# XHSC_HC32A052 register map
Vendor: XHSC Co.Ltd; Series: ARMCM4; File version: 1.2
CPU: CM0 r0p0, little endian, no MPU, no FPU, 3 interrupt priority bits
Registers are 32-bit, read-write, reset 0x0 unless marked. A register's access mark holds for its fields unless they carry their own. Offsets are from the block's base; [hi:lo] are bit positions; {n}, {i} and the like mark numbered series; 'fields as' and 'values as' point back to an identical list.

## RTC
Base 0x40001400
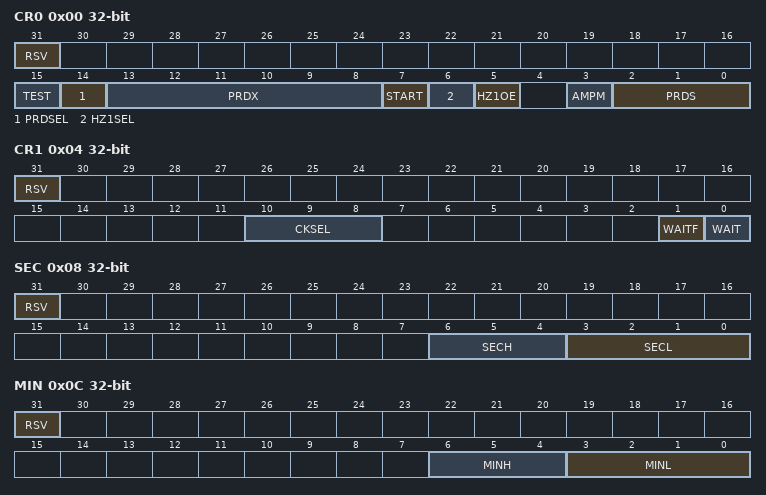
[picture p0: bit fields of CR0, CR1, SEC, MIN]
0x00 CR0 (reset mask 0xFFEF)
  [31] RSV, [15] TEST, [14] PRDSEL, [13:8] PRDX, [7] START, [6] HZ1SEL, [5] HZ1OE, [3] AMPM, [2:0] PRDS
0x04 CR1 (reset mask 0x303)
  [31] RSV, [10:8] CKSEL, [1] WAITF, [0] WAIT
0x08 SEC (reset mask 0x7F)
  [31] RSV, [6:4] SECH, [3:0] SECL
0x0C MIN (reset mask 0x7F)
  [31] RSV, [6:4] MINH, [3:0] MINL
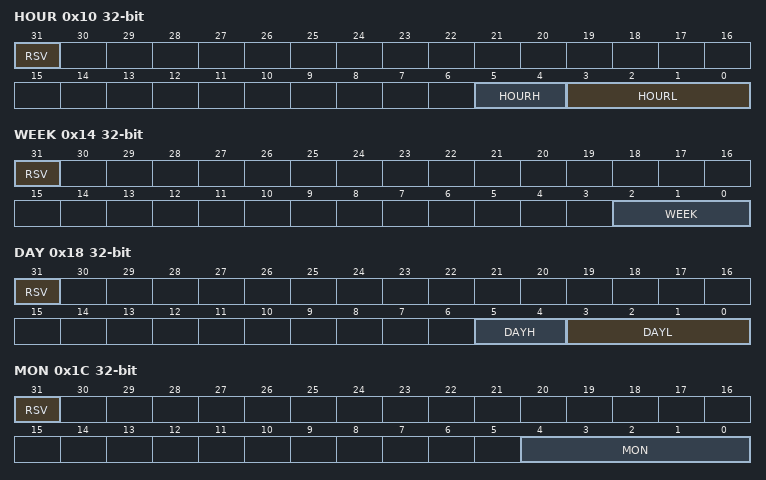
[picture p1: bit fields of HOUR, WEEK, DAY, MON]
0x10 HOUR (reset mask 0x3F)
  [31] RSV, [5:4] HOURH, [3:0] HOURL
0x14 WEEK (reset mask 0x7)
  [31] RSV, [2:0] WEEK
0x18 DAY (reset mask 0x3F)
  [31] RSV, [5:4] DAYH, [3:0] DAYL
0x1C MON (reset mask 0x1F)
  [31] RSV, [4:0] MON
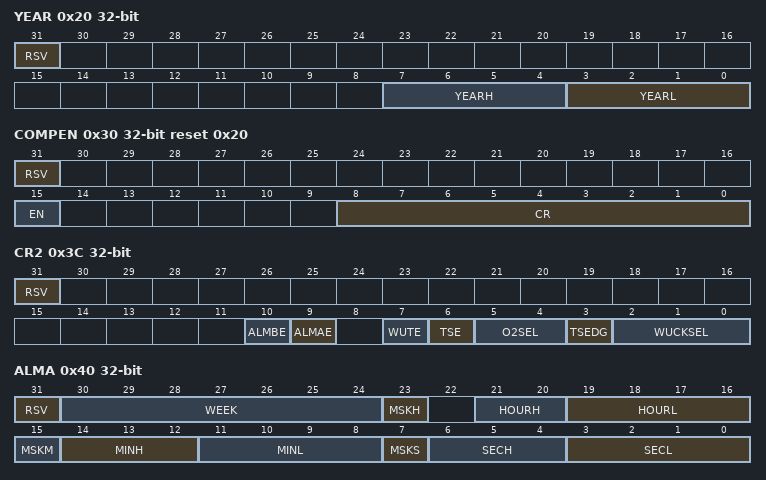
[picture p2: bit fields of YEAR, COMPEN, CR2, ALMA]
0x20 YEAR (reset mask 0xFF)
  [31] RSV, [7:4] YEARH, [3:0] YEARL
0x30 COMPEN reset 0x20 (reset mask 0x18FF)
  [31] RSV, [15] EN, [8:0] CR
0x3C CR2 (reset mask 0x6FF)
  [31] RSV, [10] ALMBE, [9] ALMAE, [7] WUTE, [6] TSE, [5:4] O2SEL, [3] TSEDG, [2:0] WUCKSEL
0x40 ALMA (reset mask 0x7FBFFFFF)
  [31] RSV, [30:24] WEEK, [23] MSKH, [21:20] HOURH, [19:16] HOURL, [15] MSKM, [14:12] MINH, [11:8] MINL, [7] MSKS, [6:4] SECH, [3:0] SECL
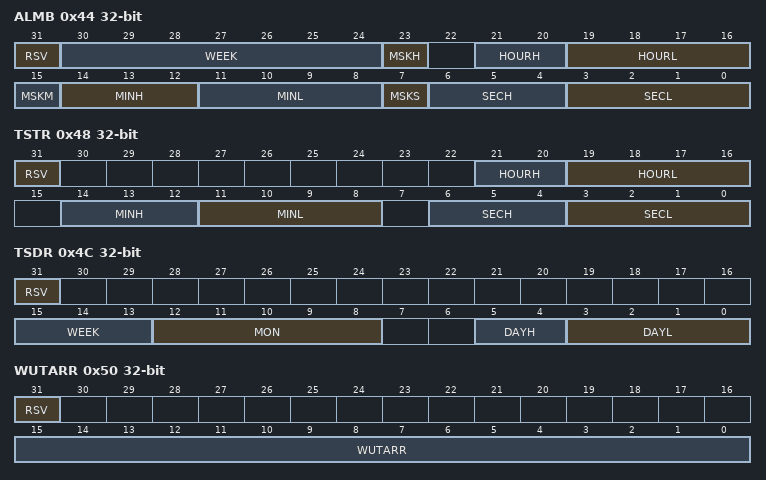
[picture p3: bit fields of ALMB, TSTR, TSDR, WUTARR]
0x44 ALMB (reset mask 0x7FBFFFFF)
  fields as ALMA
0x48 TSTR ro (reset mask 0x3F7F7F)
  [31] RSV, [21:20] HOURH, [19:16] HOURL, [14:12] MINH, [11:8] MINL, [6:4] SECH, [3:0] SECL
0x4C TSDR ro (reset mask 0xFF3F)
  [31] RSV, [15:13] WEEK, [12:8] MON, [5:4] DAYH, [3:0] DAYL
0x50 WUTARR (reset mask 0xFFFF)
  [31] RSV, [15:0] WUTARR
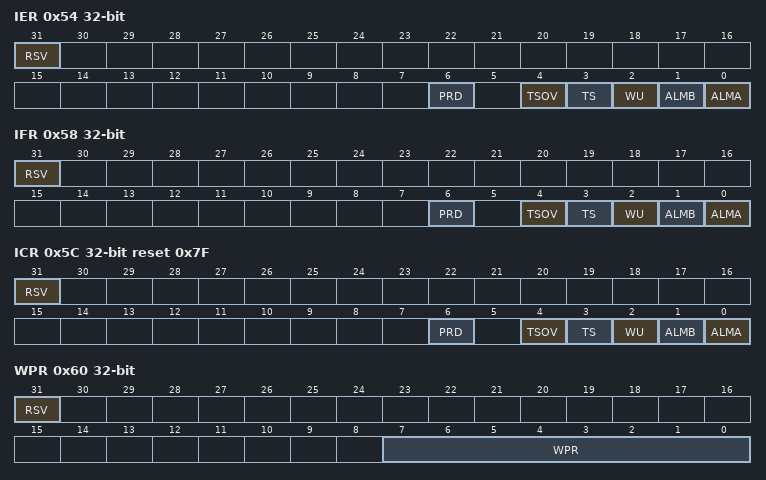
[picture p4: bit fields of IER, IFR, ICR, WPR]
0x54 IER (reset mask 0x5F)
  [31] RSV, [6] PRD, [4] TSOV, [3] TS, [2] WU, [1] ALMB, [0] ALMA
0x58 IFR ro (reset mask 0x5F)
  [31] RSV, [6] PRD, [4] TSOV, [3] TS, [2] WU, [1] ALMB, [0] ALMA
0x5C ICR reset 0x7F (reset mask 0x5F)
  [31] RSV, [6] PRD, [4] TSOV, [3] TS, [2] WU, [1] ALMB, [0] ALMA
0x60 WPR (reset mask 0xFF)
  [31] RSV, [7:0] WPR

## SPI0 — desc SPI
Base 0x40000800
Same registers: SPI1 0x40004800
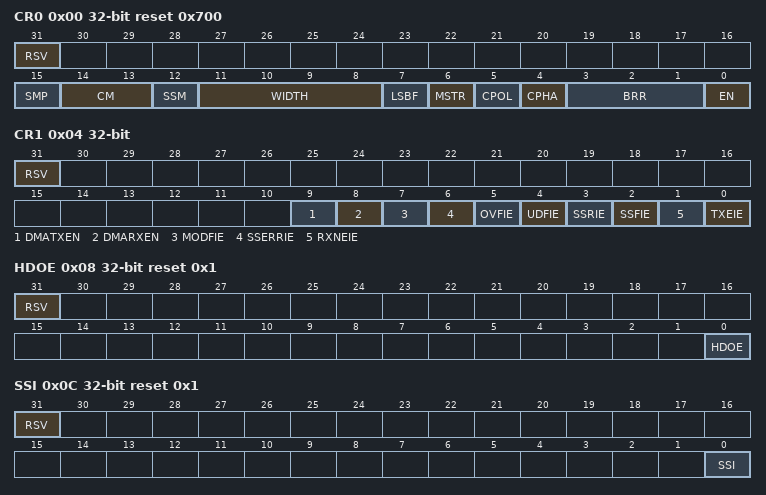
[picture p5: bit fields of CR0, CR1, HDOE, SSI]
0x00 CR0 reset 0x700 (reset mask 0xFFFF)
  [31] RSV, [15] SMP, [14:13] CM, [12] SSM, [11:8] WIDTH, [7] LSBF, [6] MSTR, [5] CPOL, [4] CPHA, [3:1] BRR, [0] EN
0x04 CR1 (reset mask 0x3FF)
  [31] RSV, [9] DMATXEN, [8] DMARXEN, [7] MODFIE, [6] SSERRIE, [5] OVFIE, [4] UDFIE, [3] SSRIE, [2] SSFIE, [1] RXNEIE, [0] TXEIE
0x08 HDOE reset 0x1 (reset mask 0x1)
  [31] RSV, [0] HDOE
0x0C SSI reset 0x1 (reset mask 0x1)
  [31] RSV, [0] SSI
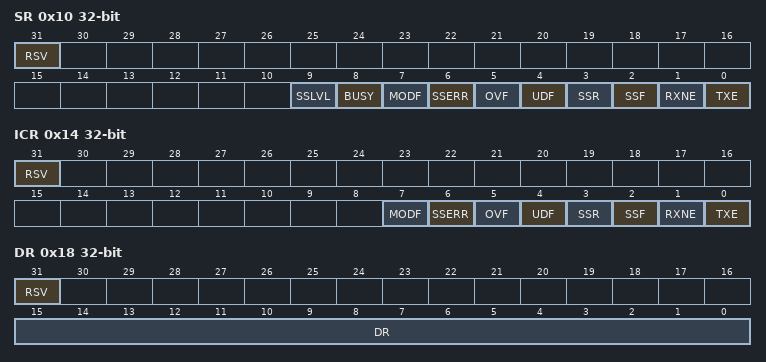
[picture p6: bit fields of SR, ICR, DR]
0x10 SR ro (reset mask 0x3FF)
  [31] RSV, [9] SSLVL, [8] BUSY, [7] MODF, [6] SSERR, [5] OVF, [4] UDF, [3] SSR, [2] SSF, [1] RXNE, [0] TXE
0x14 ICR wo (reset mask 0xBE)
  [31] RSV, [7] MODF, [6] SSERR, [5] OVF, [4] UDF, [3] SSR, [2] SSF, [1] RXNE, [0] TXE
0x18 DR (reset mask 0xFF)
  [31] RSV, [15:0] DR

## SYSCTRL
Base 0x40002000; alternate view of GPIOAUX
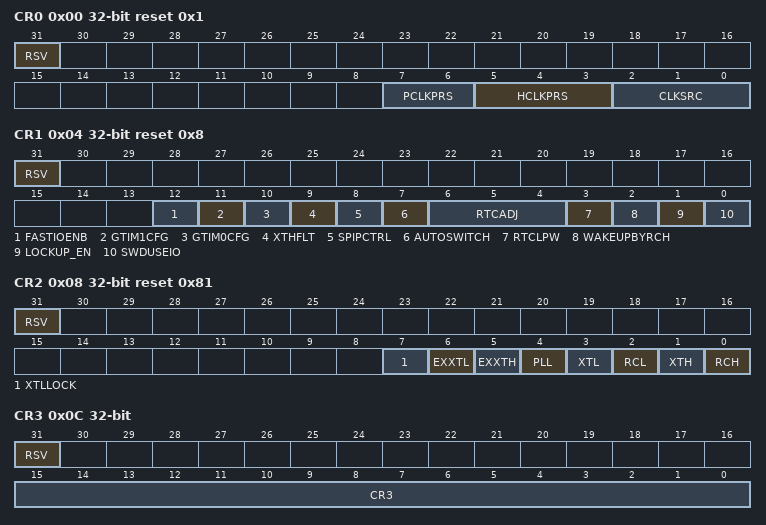
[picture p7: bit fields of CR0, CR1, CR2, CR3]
0x00 CR0 reset 0x1 (reset mask 0xFF)
  [31] RSV, [7:6] PCLKPRS, [5:3] HCLKPRS, [2:0] CLKSRC
0x04 CR1 reset 0x8 (reset mask 0x1FFF)
  [31] RSV, [12] FASTIOENB, [11] GTIM1CFG, [10] GTIM0CFG, [9] XTHFLT, [8] SPIPCTRL, [7] AUTOSWITCH, [6:4] RTCADJ, [3] RTCLPW, [2] WAKEUPBYRCH, [1] LOCKUP_EN, [0] SWDUSEIO
0x08 CR2 reset 0x81 (reset mask 0xFF)
  [31] RSV, [7] XTLLOCK, [6] EXXTL, [5] EXXTH, [4] PLL, [3] XTL, [2] RCL, [1] XTH, [0] RCH
0x0C CR3 wo (reset mask 0xFFFF)
  [31] RSV rw, [15:0] CR3
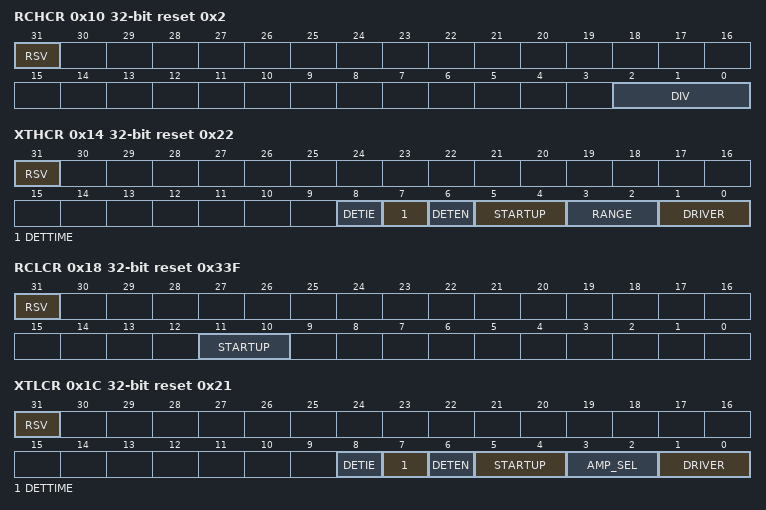
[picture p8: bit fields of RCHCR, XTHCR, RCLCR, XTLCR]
0x10 RCHCR reset 0x2 (reset mask 0x7)
  [31] RSV, [2:0] DIV
0x14 XTHCR reset 0x22 (reset mask 0x1FF)
  [31] RSV, [8] DETIE, [7] DETTIME, [6] DETEN, [5:4] STARTUP, [3:2] RANGE, [1:0] DRIVER
0x18 RCLCR reset 0x33F (reset mask 0xC00)
  [31] RSV, [11:10] STARTUP
0x1C XTLCR reset 0x21 (reset mask 0x1FF)
  [31] RSV, [8] DETIE, [7] DETTIME, [6] DETEN, [5:4] STARTUP, [3:2] AMP_SEL, [1:0] DRIVER
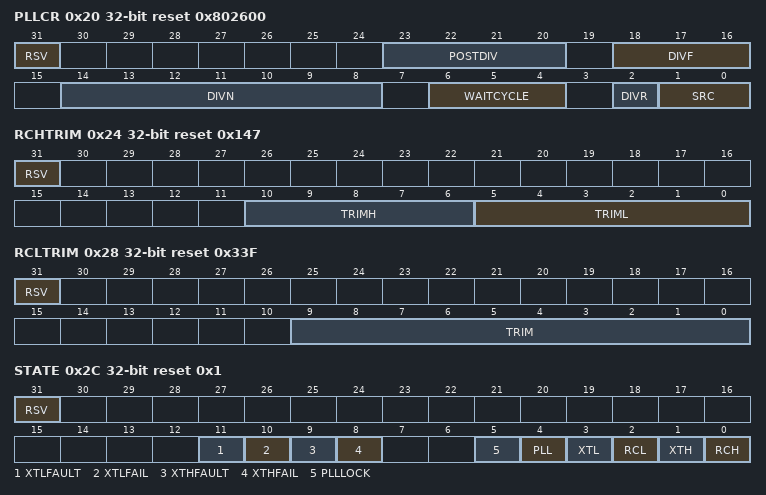
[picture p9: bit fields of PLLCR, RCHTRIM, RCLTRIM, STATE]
0x20 PLLCR reset 0x802600 (reset mask 0xF77F77)
  [31] RSV, [23:20] POSTDIV, [18:16] DIVF, [14:8] DIVN, [6:4] WAITCYCLE, [2] DIVR, [1:0] SRC
0x24 RCHTRIM reset 0x147 (reset mask 0x7FF)
  [31] RSV, [10:6] TRIMH, [5:0] TRIML
0x28 RCLTRIM reset 0x33F (reset mask 0x3FF)
  [31] RSV, [9:0] TRIM
0x2C STATE reset 0x1 (reset mask 0xFFF)
  [31] RSV, [11] XTLFAULT, [10] XTLFAIL, [9] XTHFAULT, [8] XTHFAIL, [5] PLLLOCK, [4] PLL, [3] XTL, [2] RCL, [1] XTH, [0] RCH
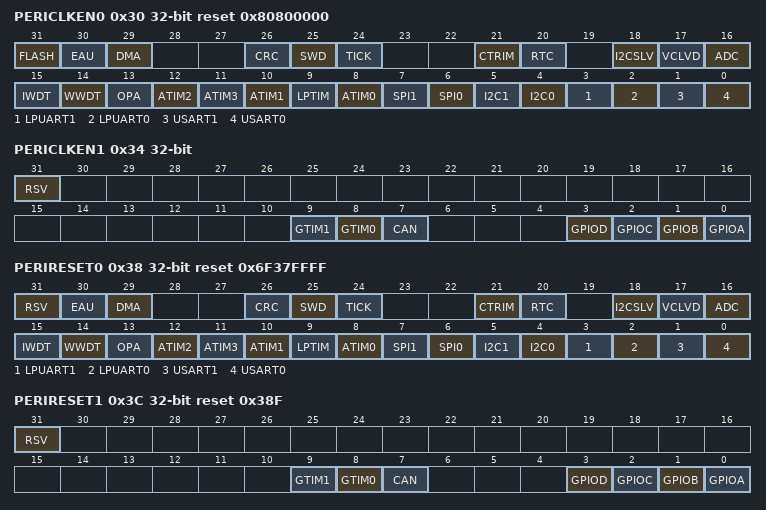
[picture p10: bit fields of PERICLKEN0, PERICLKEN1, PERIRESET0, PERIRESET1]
0x30 PERICLKEN0 reset 0x80800000
  [31] FLASH, [30] EAU, [29] DMA, [26] CRC, [25] SWD, [24] TICK, [21] CTRIM, [20] RTC, [18] I2CSLV, [17] VCLVD, [16] ADC, [15] IWDT, [14] WWDT, [13] OPA, [12] ATIM2, [11] ATIM3, [10] ATIM1, [9] LPTIM, [8] ATIM0, [7] SPI1, [6] SPI0, [5] I2C1, [4] I2C0, [3] LPUART1, [2] LPUART0, [1] USART1, [0] USART0
0x34 PERICLKEN1 (reset mask 0x38F)
  [31] RSV, [9] GTIM1, [8] GTIM0, [7] CAN, [3] GPIOD, [2] GPIOC, [1] GPIOB, [0] GPIOA
0x38 PERIRESET0 reset 0x6F37FFFF (reset mask 0x6737FFFF)
  [31] RSV, [30] EAU, [29] DMA, [26] CRC, [25] SWD, [24] TICK, [21] CTRIM, [20] RTC, [18] I2CSLV, [17] VCLVD, [16] ADC, [15] IWDT, [14] WWDT, [13] OPA, [12] ATIM2, [11] ATIM3, [10] ATIM1, [9] LPTIM, [8] ATIM0, [7] SPI1, [6] SPI0, [5] I2C1, [4] I2C0, [3] LPUART1, [2] LPUART0, [1] USART1, [0] USART0
0x3C PERIRESET1 reset 0x38F (reset mask 0x38F)
  fields as PERICLKEN1
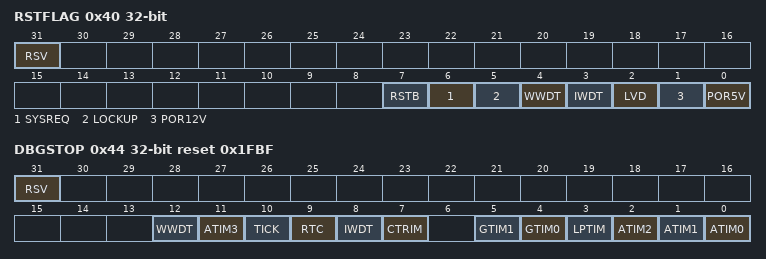
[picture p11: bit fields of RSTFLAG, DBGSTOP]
0x40 RSTFLAG (reset mask 0x1FF)
  [31] RSV, [7] RSTB, [6] SYSREQ, [5] LOCKUP, [4] WWDT, [3] IWDT, [2] LVD, [1] POR12V, [0] POR5V
0x44 DBGSTOP reset 0x1FBF (reset mask 0x1FBF)
  [31] RSV, [12] WWDT, [11] ATIM3, [10] TICK, [9] RTC, [8] IWDT, [7] CTRIM, [5] GTIM1, [4] GTIM0, [3] LPTIM, [2] ATIM2, [1] ATIM1, [0] ATIM0

## USART0 — desc USART
Base 0x40006000
Same registers: USART1 0x40006400
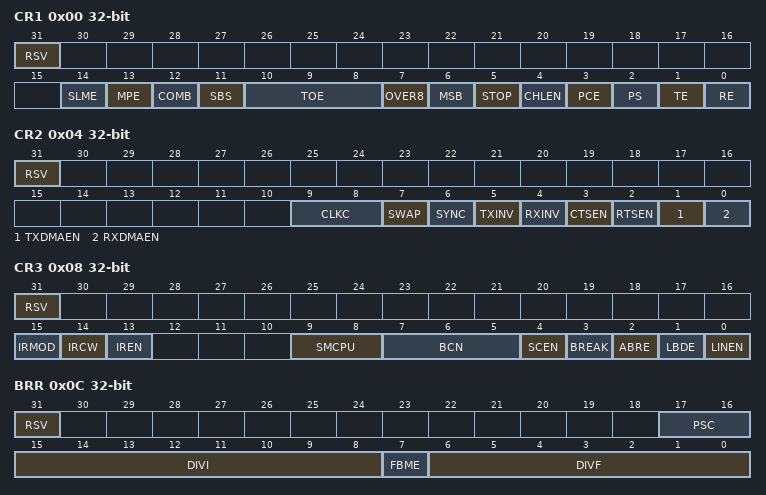
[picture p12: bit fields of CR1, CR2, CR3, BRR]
0x00 CR1 (reset mask 0x7FFF)
  [31] RSV, [14] SLME, [13] MPE, [12] COMB, [11] SBS, [10:8] TOE, [7] OVER8, [6] MSB, [5] STOP, [4] CHLEN, [3] PCE, [2] PS, [1] TE, [0] RE
0x04 CR2 (reset mask 0x3FF)
  [31] RSV, [9:8] CLKC, [7] SWAP, [6] SYNC, [5] TXINV, [4] RXINV, [3] CTSEN, [2] RTSEN, [1] TXDMAEN, [0] RXDMAEN
0x08 CR3 (reset mask 0xE3FF)
  [31] RSV, [15] IRMOD, [14] IRCW, [13] IREN, [9:8] SMCPU, [7:5] BCN, [4] SCEN, [3] BREAK, [2] ABRE, [1] LBDE, [0] LINEN
0x0C BRR (reset mask 0x3FFFF)
  [31] RSV, [17:16] PSC, [15:8] DIVI, [7] FBME, [6:0] DIVF
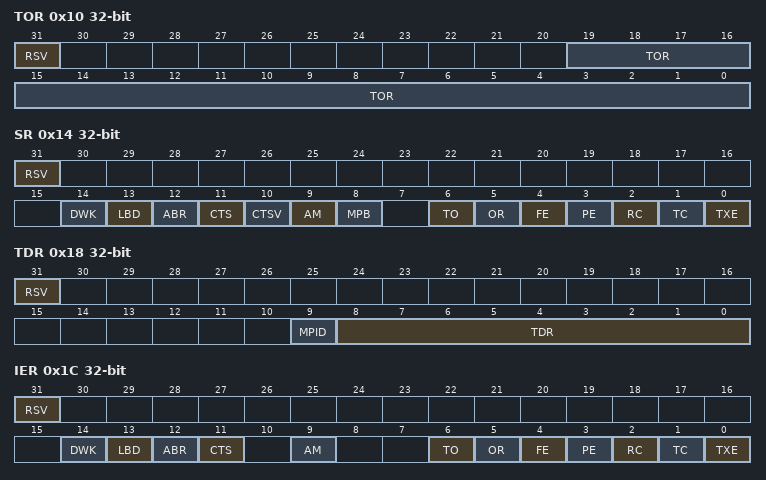
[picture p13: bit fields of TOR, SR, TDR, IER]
0x10 TOR (reset mask 0xFFFFF)
  [31] RSV, [19:0] TOR
0x14 SR ro (reset mask 0x7F7F)
  [31] RSV, [14] DWK, [13] LBD, [12] ABR, [11] CTS, [10] CTSV, [9] AM, [8] MPB, [6] TO, [5] OR, [4] FE, [3] PE, [2] RC, [1] TC, [0] TXE
0x18 TDR (reset mask 0x3FF)
  [31] RSV, [9] MPID, [8:0] TDR
0x1C IER (reset mask 0x7A7F)
  [31] RSV, [14] DWK, [13] LBD, [12] ABR, [11] CTS, [9] AM, [6] TO, [5] OR, [4] FE, [3] PE, [2] RC, [1] TC, [0] TXE
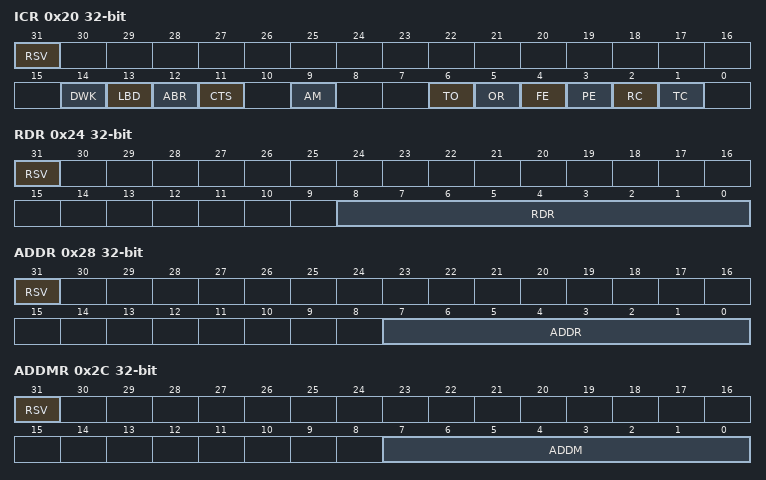
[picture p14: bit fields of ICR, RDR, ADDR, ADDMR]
0x20 ICR wo (reset mask 0x7A7E)
  [31] RSV, [14] DWK, [13] LBD, [12] ABR, [11] CTS, [9] AM, [6] TO, [5] OR, [4] FE, [3] PE, [2] RC, [1] TC
0x24 RDR ro (reset mask 0x1FF)
  [31] RSV, [8:0] RDR
0x28 ADDR (reset mask 0xFF)
  [31] RSV, [7:0] ADDR
0x2C ADDMR (reset mask 0xFF)
  [31] RSV, [7:0] ADDM
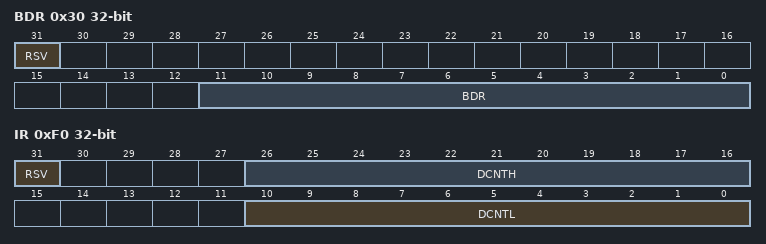
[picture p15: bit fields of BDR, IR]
0x30 BDR ro (reset mask 0xFFF)
  [31] RSV, [11:0] BDR
0xF0 IR (reset mask 0x7FF07FF)
  [31] RSV, [26:16] DCNTH, [10:0] DCNTL

## VC0 — desc VC
Base 0x40002400
Same registers: VC1 0x40002410
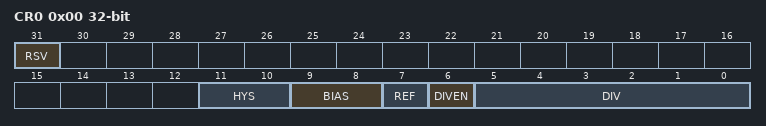
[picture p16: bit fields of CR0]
0x00 CR0 (reset mask 0xFFF)
  [31] RSV, [11:10] HYS, [9:8] BIAS, [7] REF, [6] DIVEN, [5:0] DIV
0x04 CR1 (reset mask 0x3FFFF)
  [31] RSV, [17] FLTCLK, [16] EN, [15] IE, [14] LEVEL, [13] RISING, [12] FALLING, [11:9] FLTTIME, [8] FLTEN, [7:4] NSEL, [3:0] PSEL
0x08 CR2 (reset mask 0x73)
  [31] RSV, [6] WINDOW, [5] ATIMBK, [n+1] ATIM{n}CLR (n=0..3), [0] POL
0x0C SR (reset mask 0x3)
  [31] RSV, [1] FLTV ro, [0] INTF

## WWDT
Base 0x40006800
0x00 CR0 (reset mask 0xFF)
  [31] RSV, [7] EN, [6:0] WCNT
0x04 CR1 reset 0x7F (reset mask 0x3A7F)
  [31] RSV, [13:11] PRS, [9] IE, [6:0] WINR
0x08 SR (reset mask 0x1)
  [31] RSV, [0] POV
